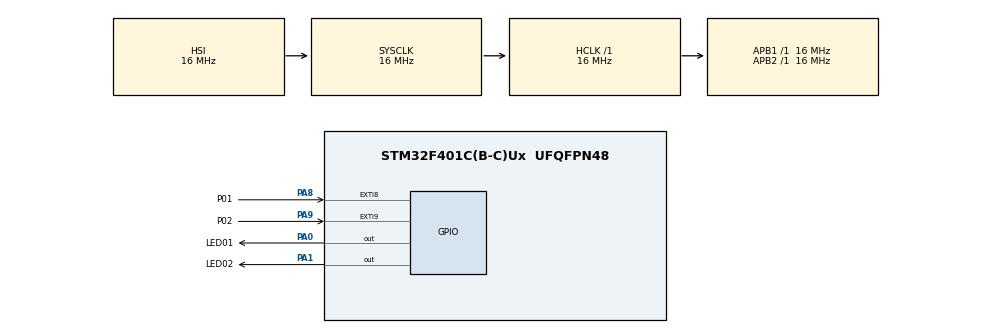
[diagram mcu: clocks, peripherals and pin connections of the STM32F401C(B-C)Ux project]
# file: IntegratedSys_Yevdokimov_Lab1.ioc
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Mcu.Family=STM32F4
Mcu.Name=STM32F401C(B-C)Ux
Mcu.Package=UFQFPN48
NVIC.EXTI9_5_IRQn=true\:5\:0\:true\:true\:true\:1\:true\:true\:true
NVIC.PriorityGroup=NVIC_PRIORITYGROUP_4
PA0-WKUP.GPIO_Label=LED01
PA0-WKUP.Signal=GPIO_Output
PA1.GPIO_Label=LED02
PA1.Signal=GPIO_Output
PA13.Mode=Serial_Wire
PA13.Signal=SYS_JTMS-SWDIO
PA14.Mode=Serial_Wire
PA14.Signal=SYS_JTCK-SWCLK
PA8.GPIO_Label=P01
PA8.GPIO_ModeDefaultEXTI=GPIO_MODE_IT_RISING
PA8.Signal=GPXTI8
PA9.GPIO_Label=P02
PA9.Signal=GPXTI9
ProjectManager.HeapSize=0x200
ProjectManager.StackSize=0x400
ProjectManager.TargetToolchain=STM32CubeIDE
RCC.AHBFreq_Value=16000000
RCC.APB1Freq_Value=16000000
RCC.APB2Freq_Value=16000000
RCC.CortexFreq_Value=16000000
RCC.HSE_VALUE=25000000
RCC.HSI_VALUE=16000000
RCC.LSE_VALUE=32768
RCC.SYSCLKFreq_VALUE=16000000
RCC.VCOOutputFreq_Value=192000000
board=custom

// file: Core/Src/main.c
/* USER CODE BEGIN Header */
/**
  ******************************************************************************
  * @file           : main.c
  * @brief          : Main program body
  ******************************************************************************
  * @attention
  *
  * Copyright (c) 2023 STMicroelectronics.
  * All rights reserved.
  *
  * This software is licensed under terms that can be found in the LICENSE file
  * in the root directory of this software component.
  * If no LICENSE file comes with this software, it is provided AS-IS.
  *
  ******************************************************************************
  */
/* USER CODE END Header */
#include "main.h"

void SystemClock_Config(void);
static void MX_GPIO_Init(void);
static void MX_NVIC_Init(void);

int main(void)
{

  /* MCU Configuration--------------------------------------------------------*/

  /* Reset of all peripherals, Initializes the Flash interface and the Systick. */
  HAL_Init();

  /* Configure the system clock */
  SystemClock_Config();

  /* Initialize all configured peripherals */
  MX_GPIO_Init();

  /* Initialize interrupts */
  MX_NVIC_Init();

  /* Infinite loop */
  while (1)
  {

  }
}

void SystemClock_Config(void)
{
  RCC_OscInitTypeDef RCC_OscInitStruct = {0};
  RCC_ClkInitTypeDef RCC_ClkInitStruct = {0};

  /** Configure the main internal regulator output voltage
  */
  __HAL_RCC_PWR_CLK_ENABLE();
  __HAL_PWR_VOLTAGESCALING_CONFIG(PWR_REGULATOR_VOLTAGE_SCALE2);

  /** Initializes the RCC Oscillators according to the specified parameters
  * in the RCC_OscInitTypeDef structure.
  */
  RCC_OscInitStruct.OscillatorType = RCC_OSCILLATORTYPE_HSI;
  RCC_OscInitStruct.HSIState = RCC_HSI_ON;
  RCC_OscInitStruct.HSICalibrationValue = RCC_HSICALIBRATION_DEFAULT;
  RCC_OscInitStruct.PLL.PLLState = RCC_PLL_NONE;
  if (HAL_RCC_OscConfig(&RCC_OscInitStruct) != HAL_OK)
  {
    Error_Handler();
  }

  /** Initializes the CPU, AHB and APB buses clocks
  */
  RCC_ClkInitStruct.ClockType = RCC_CLOCKTYPE_HCLK|RCC_CLOCKTYPE_SYSCLK
                              |RCC_CLOCKTYPE_PCLK1|RCC_CLOCKTYPE_PCLK2;
  RCC_ClkInitStruct.SYSCLKSource = RCC_SYSCLKSOURCE_HSI;
  RCC_ClkInitStruct.AHBCLKDivider = RCC_SYSCLK_DIV1;
  RCC_ClkInitStruct.APB1CLKDivider = RCC_HCLK_DIV1;
  RCC_ClkInitStruct.APB2CLKDivider = RCC_HCLK_DIV1;

  if (HAL_RCC_ClockConfig(&RCC_ClkInitStruct, FLASH_LATENCY_0) != HAL_OK)
  {
    Error_Handler();
  }
}

/**
  * @brief NVIC Configuration.
  * @retval None
  */
static void MX_NVIC_Init(void)
{
  /* EXTI9_5_IRQn interrupt configuration */
  HAL_NVIC_SetPriority(EXTI9_5_IRQn, 5, 0);
  HAL_NVIC_EnableIRQ(EXTI9_5_IRQn);
}

static void MX_GPIO_Init(void)
{
  GPIO_InitTypeDef GPIO_InitStruct = {0};

  /* GPIO Ports Clock Enable */
  __HAL_RCC_GPIOA_CLK_ENABLE();

  /*Configure GPIO pin Output Level */
  HAL_GPIO_WritePin(GPIOA, LED01_Pin|LED02_Pin, GPIO_PIN_RESET);

  /*Configure GPIO pins : LED01_Pin LED02_Pin */
  GPIO_InitStruct.Pin = LED01_Pin|LED02_Pin;
  GPIO_InitStruct.Mode = GPIO_MODE_OUTPUT_PP;
  GPIO_InitStruct.Pull = GPIO_NOPULL;
  GPIO_InitStruct.Speed = GPIO_SPEED_FREQ_LOW;
  HAL_GPIO_Init(GPIOA, &GPIO_InitStruct);

  /*Configure GPIO pins : P01_Pin P02_Pin */
  GPIO_InitStruct.Pin = P01_Pin|P02_Pin;
  GPIO_InitStruct.Mode = GPIO_MODE_IT_RISING;
  GPIO_InitStruct.Pull = GPIO_NOPULL;
  HAL_GPIO_Init(GPIOA, &GPIO_InitStruct);

}

/* USER CODE BEGIN 4 */
void WaitForCallback() {
	for(volatile int i = 0; i < 1000000; i++) { }
}

void HAL_GPIO_EXTI_Callback(uint16_t GPIO_Pin) {
	if(GPIO_Pin == P01_Pin) {
		HAL_GPIO_WritePin(LED01_GPIO_Port, LED01_Pin, GPIO_PIN_SET);
		WaitForCallback();
		HAL_GPIO_WritePin(LED01_GPIO_Port, LED01_Pin, GPIO_PIN_RESET);
	}
	else if(GPIO_Pin == P02_Pin) {
		HAL_GPIO_WritePin(LED02_GPIO_Port, LED02_Pin, GPIO_PIN_SET);
		WaitForCallback();
		HAL_GPIO_WritePin(LED02_GPIO_Port, LED02_Pin, GPIO_PIN_RESET);
	}
}
/* USER CODE END 4 */

void Error_Handler(void)
{
  __disable_irq();
  while (1)
  {
  }
}
